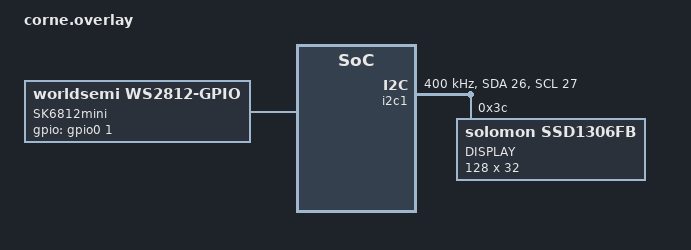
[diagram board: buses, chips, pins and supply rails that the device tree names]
/ {
    chosen {
        zmk,underglow = &led_strip;
        zmk,backlight = &led_strip;    // Если используется как подсветка клавиш
    };

    led_strip: ws2812 {
        compatible = "worldsemi,ws2812-gpio";
        label = "SK6812mini";

        // Настройки для RGB светодиодов
        chain-length = <27>;    // Количество светодиодов на половине
        spi-one-frame = <0x70>;
        spi-zero-frame = <0x40>;
        color-mapping = <LED_COLOR_ID_GREEN LED_COLOR_ID_RED LED_COLOR_ID_BLUE>;

        // GPIO настройки
        gpios = <&gpio0 1 GPIO_ACTIVE_HIGH>;
    };
};

&i2c1 {
    status = "okay";
    clock-frequency = <400000>;
    scl-pin = <27>;
    sda-pin = <26>;

    oled: ssd1306@3c {
        compatible = "solomon,ssd1306fb";
        reg = <0x3c>;
        label = "DISPLAY";
        width = <128>;
        height = <32>;
        segment-offset = <0>;
        page-offset = <0>;
        display-offset = <0>;
        multiplex-ratio = <31>;
        segment-remap;
        com-invdir;
        com-sequential;
        prechargep = <0x22>;
    };
};

&spi1 {
    status = "disabled";       // Отключаем SPI, если он конфликтует с I2C
};
